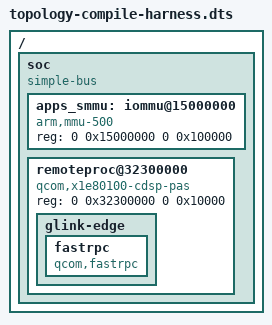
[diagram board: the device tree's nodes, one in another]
/dts-v1/;
/ {
	#address-cells = <2>;
	#size-cells = <2>;
	soc {
		compatible = "simple-bus";
		#address-cells = <2>;
		#size-cells = <2>;
		ranges;
		apps_smmu: iommu@15000000 {
			compatible = "arm,mmu-500";
			reg = <0 0x15000000 0 0x100000>;
			#iommu-cells = <2>;
		};
		remoteproc@32300000 {
			compatible = "qcom,x1e80100-cdsp-pas";
			reg = <0 0x32300000 0 0x10000>;
			glink-edge {
				fastrpc {
					compatible = "qcom,fastrpc";
					#address-cells = <1>;
					#size-cells = <0>;
					/include/ "hamoa-secure-cb9-candidate.dtsi"
				};
			};
		};
	};
};
